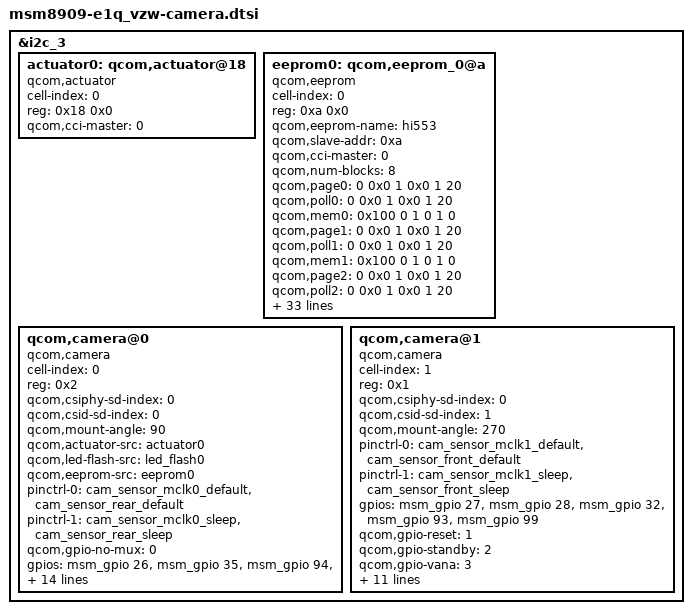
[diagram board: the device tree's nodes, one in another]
/*
 * Copyright (c) 2014, The Linux Foundation. All rights reserved.
 *
 * This program is free software; you can redistribute it and/or modify
 * it under the terms of the GNU General Public License version 2 and
 * only version 2 as published by the Free Software Foundation.
 *
 * This program is distributed in the hope that it will be useful,
 * but WITHOUT ANY WARRANTY; without even the implied warranty of
 * MERCHANTABILITY or FITNESS FOR A PARTICULAR PURPOSE.  See the
 * GNU General Public License for more details.
 */

#include "../msm8909-lge-common/msm8909-backlight-rt8542.dtsi"
&i2c_3 {
	actuator0: qcom,actuator@18 {
		cell-index = <0>;
		reg = <0x18 0x0>;
		compatible = "qcom,actuator";
		qcom,cci-master = <0>;
	};

	eeprom0: qcom,eeprom_0@a {
		cell-index       = <0>;
		reg              = <0xa 0x0>;
		qcom,eeprom-name = "hi553";
		compatible       = "qcom,eeprom";
		qcom,slave-addr  = <0xa>;
		qcom,cci-master  = <0>;

		qcom,num-blocks = <8>;

		qcom,page0 = <0 0x0 1 0x0 1 20>; // valid size, addr, addr_t, data, data_t, delay
		qcom,poll0 = <0 0x0 1 0x0 1 20>;
		qcom,mem0  = <0x100 0 1 0 1 0>; //EEPROM READ

		qcom,page1 = <0 0x0 1 0x0 1 20>;
		qcom,poll1 = <0 0x0 1 0x0 1 20>;
		qcom,mem1  = <0x100 0 1 0 1 0>;

		qcom,page2 = <0 0x0 1 0x0 1 20>;
		qcom,poll2 = <0 0x0 1 0x0 1 20>;
		qcom,mem2  = <0x100 0 1 0 1 0>;

		qcom,page3 = <0 0x0 1 0x0 1 20>;
		qcom,poll3 = <0 0x0 1 0x0 1 20>;
		qcom,mem3  = <0x100 0 1 0 1 0>;

		qcom,page4 = <0 0x0 1 0x0 1 20>; // valid size, addr, addr_t, data, data_t, delay
		qcom,poll4 = <0 0x0 1 0x0 1 20>;
		qcom,mem4  = <0x100 0 1 0 1 0>; //EEPROM READ

		qcom,page5 = <0 0x0 1 0x0 1 20>;
		qcom,poll5 = <0 0x0 1 0x0 1 20>;
		qcom,mem5  = <0x100 0 1 0 1 0>;

		qcom,page6 = <0 0x0 1 0x0 1 20>;
		qcom,poll6 = <0 0x0 1 0x0 1 20>;
		qcom,mem6  = <0x100 0 1 0 1 0>;

		qcom,page7 = <0 0x0 1 0x0 1 20>;
		qcom,poll7 = <0 0x0 1 0x0 1 20>;
		qcom,mem7  = <0x100 0 1 0 1 0>;

		pinctrl-names = "cam_default", "cam_suspend";
		pinctrl-0 = <&cam_sensor_mclk0_default &cam_sensor_rear_default>;
		pinctrl-1 = <&cam_sensor_mclk0_sleep &cam_sensor_rear_sleep>;

		gpios = <&msm_gpio 26 0>,    //MAIN_CAM0_MCLK
		        <&msm_gpio 35 0>;    //MAIN_CAM0_RESET_N --> StandBY

		qcom,gpio-no-mux = <0>;
		qcom,gpio-reset   = <1>;

		qcom,gpio-req-tbl-num	= <0 1>;
		qcom,gpio-req-tbl-flags	= <1 0>;
		qcom,gpio-req-tbl-label = "CAMIF_MCLK", "CAM_RESET1";

		qcom,csi-lane-assign = <0x4320>;
		qcom,csi-lane-mask   = <0x07>;

		qcom,cam-power-seq-type = "sensor_gpio";
		qcom,cam-power-seq-val  = "sensor_gpio_reset";
		qcom,cam-power-seq-cfg-val = <1>;
		qcom,cam-power-seq-delay   = <1>;
	};

	qcom,camera@0 {
		cell-index = <0>;
		compatible = "qcom,camera";
		reg = <0x2>;
		qcom,csiphy-sd-index = <0>;
		qcom,csid-sd-index = <0>;
		qcom,mount-angle = <90>;
		qcom,actuator-src = <&actuator0>;
		qcom,led-flash-src = <&led_flash0>;
		qcom,eeprom-src = <&eeprom0>;

		pinctrl-names = "cam_default", "cam_suspend";
		pinctrl-0 = <&cam_sensor_mclk0_default
				&cam_sensor_rear_default>;
		pinctrl-1 = <&cam_sensor_mclk0_sleep &cam_sensor_rear_sleep>;
		qcom,gpio-no-mux = <0>;
		gpios = <&msm_gpio 26 0>,   //MAIN_CAM0_MCLK
				<&msm_gpio 35 0>,	//MAIN_CAM0_RESET_N --> StandB
				<&msm_gpio 94 0>,	//CAM_DVDD
				<&msm_gpio 93 0>; 	//CAM_AVDD

		qcom,gpio-reset   = <1>;
		qcom,gpio-custom1    = <2>;
		qcom,gpio-vana    = <3>;

		qcom,gpio-req-tbl-num	= <0 1 2 3>;
		qcom,gpio-req-tbl-flags	= <1 0 0 0>;
		qcom,gpio-req-tbl-label = "CAMIF_MCLK", "CAM_RESET1", "CAM_CUSTOM1", "CAM_AVDD";
		qcom,csi-lane-assign = <0x4320>;
		qcom,csi-lane-mask   = <0x07>;
		qcom,sensor-position = <0>;
		qcom,sensor-mode = <0>;

		status = "ok";
		clocks = <&clock_gcc clk_mclk0_clk_src>,
				<&clock_gcc clk_gcc_camss_mclk0_clk>;
		clock-names = "cam_src_clk", "cam_clk";
	};

	qcom,camera@1 {
		cell-index = <1>;
		compatible = "qcom,camera";
		reg = <0x1>;
		qcom,csiphy-sd-index = <0>;
		qcom,csid-sd-index = <1>;
		qcom,mount-angle = <270>;
		
		pinctrl-names = "cam_default", "cam_suspend";
		pinctrl-0 = <&cam_sensor_mclk1_default &cam_sensor_front_default>;
		pinctrl-1 = <&cam_sensor_mclk1_sleep &cam_sensor_front_sleep>;
		gpios = <&msm_gpio 27 0>,
			<&msm_gpio 28 0>,	//VT_CAM_RESET
			<&msm_gpio 32 0>,	//VT_CAM_PWDN
			<&msm_gpio 93 0>,	//2V8_CAM_AVDD
			<&msm_gpio 99 0>;	//1V8_CAM_DVDD


		qcom,gpio-reset = <1>;
		qcom,gpio-standby = <2>;
		qcom,gpio-vana = <3>;
		qcom,gpio-custom2 = <4>;

		qcom,gpio-req-tbl-num = <0 1 2 3 4>;
		qcom,gpio-req-tbl-flags = <1 0 0 0 0>;
		qcom,gpio-req-tbl-label = "CAMIF_MCLK", "CAM_PWDN", "CAM_RESET1", "CAM_AVDD", "CAM_CUSTOM2";
		qcom,csi-lane-assign = <0x0004>;
		qcom,csi-lane-mask = <0x18>;
		qcom,sensor-position = <1>;
		qcom,sensor-mode = <1>;
		status = "ok";
		clocks = <&clock_gcc clk_mclk1_clk_src>,
		         <&clock_gcc clk_gcc_camss_mclk1_clk>;
		clock-names = "cam_src_clk", "cam_clk";
	};

};
